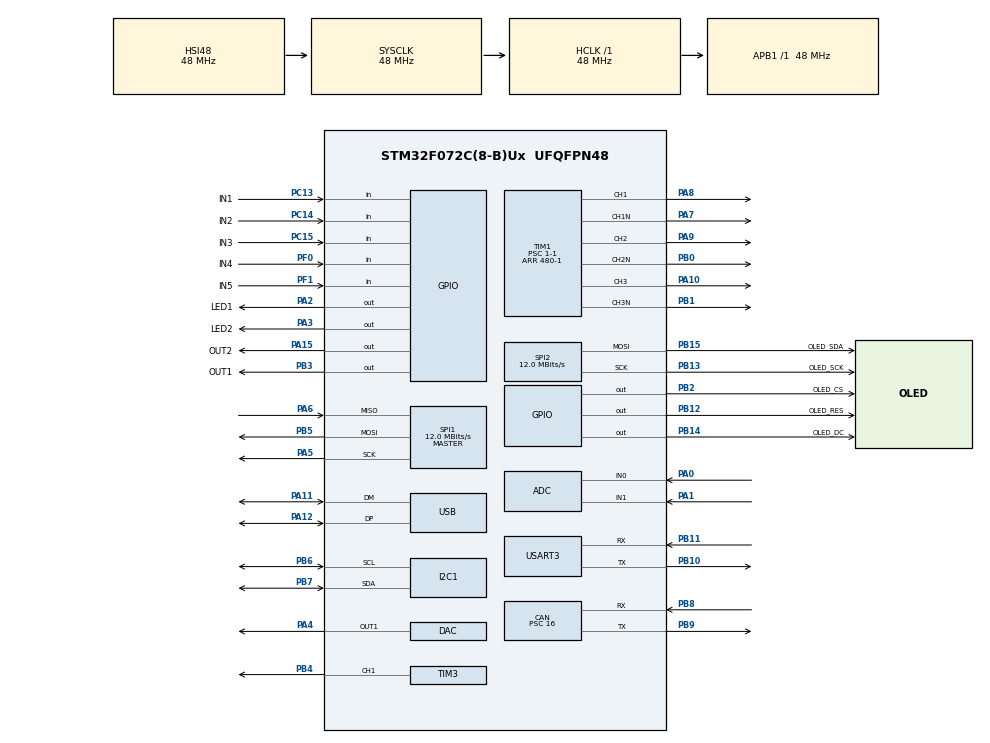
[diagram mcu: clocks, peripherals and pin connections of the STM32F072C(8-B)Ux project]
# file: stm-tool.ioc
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CAN.ABOM=ENABLE
CAN.BS1=CAN_BS1_15TQ
CAN.BS2=CAN_BS2_8TQ
CAN.CalculateBaudRate=125000
CAN.CalculateTimeBit=8000
CAN.CalculateTimeQuantum=333.3333333333333
CAN.NART=ENABLE
CAN.Prescaler=16
CAN.SJW=CAN_SJW_1TQ
CAN.TXFP=DISABLE
Mcu.Family=STM32F0
Mcu.Name=STM32F072C(8-B)Ux
Mcu.Package=UFQFPN48
NVIC.CEC_CAN_IRQn=true\:0\:0\:false\:false\:true\:true\:true\:true
NVIC.TIM15_IRQn=true\:0\:0\:false\:false\:true\:true\:true\:true
NVIC.USB_IRQn=true\:0\:0\:false\:false\:true\:false\:true\:true
PA0.Mode=IN0
PA0.Signal=ADC_IN0
PA1.Mode=IN1
PA1.Signal=ADC_IN1
PA10.Signal=S_TIM1_CH3
PA11.Mode=Device
PA11.Signal=USB_DM
PA12.Mode=Device
PA12.Signal=USB_DP
PA13.Mode=Serial_Wire
PA13.Signal=SYS_SWDIO
PA14.Mode=Serial_Wire
PA14.Signal=SYS_SWCLK
PA15.GPIO_Label=OUT2
PA15.Signal=GPIO_Output
PA2.GPIO_Label=LED1
PA2.Signal=GPIO_Output
PA3.GPIO_Label=LED2
PA3.Signal=GPIO_Output
PA4.Signal=COMP_DAC1_group
PA5.Mode=Full_Duplex_Master
PA5.Signal=SPI1_SCK
PA6.Mode=Full_Duplex_Master
PA6.Signal=SPI1_MISO
PA7.Mode=PWM Generation1 CH1 CH1N
PA7.Signal=TIM1_CH1N
PA8.Signal=S_TIM1_CH1
PA9.Signal=S_TIM1_CH2
PB0.Mode=Output Compare2 CH2 CH2N
PB0.Signal=TIM1_CH2N
PB1.Mode=PWM Generation3 CH3 CH3N
PB1.Signal=TIM1_CH3N
PB10.Mode=Asynchronous
PB10.Signal=USART3_TX
PB11.Mode=Asynchronous
PB11.Signal=USART3_RX
PB12.GPIO_Label=OLED_RES
PB12.GPIO_Speed=GPIO_SPEED_FREQ_HIGH
PB12.Signal=GPIO_Output
PB13.GPIO_Label=OLED_SCK
PB13.Mode=TX_Only_Simplex_Unidirect_Master
PB13.Signal=SPI2_SCK
PB14.GPIO_Label=OLED_DC
PB14.GPIO_Speed=GPIO_SPEED_FREQ_HIGH
PB14.Signal=GPIO_Output
PB15.GPIO_Label=OLED_SDA
PB15.Mode=TX_Only_Simplex_Unidirect_Master
PB15.Signal=SPI2_MOSI
PB2.GPIO_Label=OLED_CS
PB2.GPIO_Speed=GPIO_SPEED_FREQ_HIGH
PB2.Signal=GPIO_Output
PB3.GPIO_Label=OUT1
PB3.Signal=GPIO_Output
PB4.Signal=S_TIM3_CH1
PB5.Mode=Full_Duplex_Master
PB5.Signal=SPI1_MOSI
PB6.Mode=I2C
PB6.Signal=I2C1_SCL
PB7.Mode=I2C
PB7.Signal=I2C1_SDA
PB8.Mode=CAN_Activate
PB8.Signal=CAN_RX
PB9.Mode=CAN_Activate
PB9.Signal=CAN_TX
PC13.GPIO_Label=IN1
PC13.GPIO_PuPd=GPIO_PULLUP
PC13.Signal=GPIO_Input
PC14-OSC32_IN.GPIO_Label=IN2
PC14-OSC32_IN.GPIO_PuPd=GPIO_PULLUP
PC14-OSC32_IN.Signal=GPIO_Input
PC15-OSC32_OUT.GPIO_Label=IN3
PC15-OSC32_OUT.GPIO_PuPd=GPIO_PULLUP
PC15-OSC32_OUT.Signal=GPIO_Input
PF0-OSC_IN.GPIO_Label=IN4
PF0-OSC_IN.GPIO_PuPd=GPIO_PULLUP
PF0-OSC_IN.Signal=GPIO_Input
PF1-OSC_OUT.GPIO_Label=IN5
PF1-OSC_OUT.GPIO_PuPd=GPIO_PULLUP
PF1-OSC_OUT.Signal=GPIO_Input
ProjectManager.HeapSize=0x400
ProjectManager.StackSize=0x800
ProjectManager.TargetToolchain=Makefile
RCC.AHBFreq_Value=48000000
RCC.APB1Freq_Value=48000000
RCC.APB1TimFreq_Value=48000000
RCC.HCLKFreq_Value=48000000
RCC.SYSCLKFreq_VALUE=48000000
RCC.SYSCLKSource=RCC_SYSCLKSOURCE_HSI48
SH.COMP_DAC1_group.0=DAC_OUT1,DAC_OUT1
SH.S_TIM1_CH1.0=TIM1_CH1,PWM Generation1 CH1 CH1N
SH.S_TIM1_CH2.0=TIM1_CH2,Output Compare2 CH2 CH2N
SH.S_TIM1_CH3.0=TIM1_CH3,PWM Generation3 CH3 CH3N
SH.S_TIM3_CH1.0=TIM3_CH1,PWM Generation1 CH1
SPI1.BaudRatePrescaler=SPI_BAUDRATEPRESCALER_4
SPI1.CalculateBaudRate=12.0 MBits/s
SPI1.DataSize=SPI_DATASIZE_8BIT
SPI1.Direction=SPI_DIRECTION_2LINES
SPI1.Mode=SPI_MODE_MASTER
SPI1.VirtualType=VM_MASTER
SPI2.BaudRatePrescaler=SPI_BAUDRATEPRESCALER_4
SPI2.CalculateBaudRate=12.0 MBits/s
SPI2.DataSize=SPI_DATASIZE_8BIT
SPI2.Direction=SPI_DIRECTION_2LINES
SPI2.Mode=SPI_MODE_MASTER
SPI2.NSSPMode=SPI_NSS_PULSE_DISABLE
SPI2.VirtualType=VM_MASTER
TIM1.AutoReloadPreload=TIM_AUTORELOAD_PRELOAD_ENABLE
TIM1.Channel-Output\ Compare2\ CH2\ CH2N=TIM_CHANNEL_2
TIM1.Channel-PWM\ Generation1\ CH1\ CH1N=TIM_CHANNEL_1
TIM1.Channel-PWM\ Generation3\ CH3\ CH3N=TIM_CHANNEL_3
TIM1.DeadTime=5
TIM1.Period=480-1
TIM1.Prescaler=1-1
TIM1.Pulse-Output\ Compare2\ CH2\ CH2N=240
TIM1.Pulse-PWM\ Generation1\ CH1\ CH1N=240
TIM1.Pulse-PWM\ Generation3\ CH3\ CH3N=240
TIM15.AutoReloadPreload=TIM_AUTORELOAD_PRELOAD_ENABLE
TIM15.Channel-PWM\ Generation1\ No\ Output=TIM_CHANNEL_1
TIM15.Channel-PWM\ Generation2\ No\ Output=TIM_CHANNEL_2
TIM15.Period=100-1
TIM15.Prescaler=48-1
TIM15.Pulse-PWM\ Generation1\ No\ Output=10
TIM15.Pulse-PWM\ Generation2\ No\ Output=20
TIM2.Channel-PWM\ Generation1\ CH1=TIM_CHANNEL_1
TIM3.Channel-PWM\ Generation1\ CH1=TIM_CHANNEL_1
USART3.VirtualMode-Asynchronous=VM_ASYNC
USB_DEVICE.CLASS_NAME_FS=CDC
USB_DEVICE.VirtualMode=Cdc
USB_DEVICE.VirtualModeFS=Cdc_FS
VP_TIM15_VS_ClockSourceINT.Mode=Internal
VP_TIM15_VS_no_output1.Mode=PWM Generation1 No Output
VP_TIM15_VS_no_output2.Mode=PWM Generation2 No Output
VP_TIM1_VS_ClockSourceINT.Mode=Internal
VP_TIM2_VS_ClockSourceINT.Mode=Internal
VP_TIM3_VS_ClockSourceINT.Mode=Internal
VP_USB_DEVICE_VS_USB_DEVICE_CDC_FS.Mode=CDC_FS
board=custom

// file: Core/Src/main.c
/* USER CODE BEGIN Header */
/**
  ******************************************************************************
  * @file           : main.c
  * @brief          : Main program body
  ******************************************************************************
  * @attention
  *
  * Copyright (c) 2024 STMicroelectronics.
  * All rights reserved.
  *
  * This software is licensed under terms that can be found in the LICENSE file
  * in the root directory of this software component.
  * If no LICENSE file comes with this software, it is provided AS-IS.
  *
  ******************************************************************************
  */
/* USER CODE END Header */
#include "main.h"
#include "adc.h"
#include "can.h"
#include "dac.h"
#include "i2c.h"
#include "spi.h"
#include "tim.h"
#include "usart.h"
#include "usb_device.h"
#include "gpio.h"

/* USER CODE BEGIN Includes */
#include "loop.h"
#include "shell_port.h"
/* USER CODE END Includes */

void SystemClock_Config(void);

int main(void)
{

  /* MCU Configuration--------------------------------------------------------*/

  /* Reset of all peripherals, Initializes the Flash interface and the Systick. */
  HAL_Init();

  /* Configure the system clock */
  SystemClock_Config();

  /* Initialize all configured peripherals */
  MX_GPIO_Init();
  MX_ADC_Init();
  MX_CAN_Init();
  MX_DAC_Init();
  MX_I2C1_Init();
  MX_SPI1_Init();
  MX_TIM1_Init();
  MX_TIM2_Init();
  MX_TIM3_Init();
  MX_USB_DEVICE_Init();
  MX_SPI2_Init();
  MX_USART3_UART_Init();
  MX_TIM15_Init();
  /* USER CODE BEGIN 2 */
    MY_Init();
    userShellInit();
    uint8_t test[2] = {0x81, 0x12};
    HAL_TIM_PWM_Start(&htim1, TIM_CHANNEL_1);
    HAL_TIMEx_PWMN_Start(&htim1, TIM_CHANNEL_1);
    HAL_TIM_PWM_Start(&htim1, TIM_CHANNEL_2);
    HAL_TIMEx_PWMN_Start(&htim1, TIM_CHANNEL_2);
    HAL_TIM_PWM_Start(&htim1, TIM_CHANNEL_3);
    HAL_TIMEx_PWMN_Start(&htim1, TIM_CHANNEL_3);
  /* USER CODE END 2 */

  /* Infinite loop */
  while (1)
  {

    /* USER CODE BEGIN 3 */
    //CAN_Send(0x123, test, 2);
    RUN_UI();
    USRshellRUN();

  }
  /* USER CODE END 3 */
}

void SystemClock_Config(void)
{
  RCC_OscInitTypeDef RCC_OscInitStruct = {0};
  RCC_ClkInitTypeDef RCC_ClkInitStruct = {0};
  RCC_PeriphCLKInitTypeDef PeriphClkInit = {0};

  /** Initializes the RCC Oscillators according to the specified parameters
  * in the RCC_OscInitTypeDef structure.
  */
  RCC_OscInitStruct.OscillatorType = RCC_OSCILLATORTYPE_HSI|RCC_OSCILLATORTYPE_HSI14
                              |RCC_OSCILLATORTYPE_HSI48;
  RCC_OscInitStruct.HSIState = RCC_HSI_ON;
  RCC_OscInitStruct.HSI48State = RCC_HSI48_ON;
  RCC_OscInitStruct.HSI14State = RCC_HSI14_ON;
  RCC_OscInitStruct.HSICalibrationValue = RCC_HSICALIBRATION_DEFAULT;
  RCC_OscInitStruct.HSI14CalibrationValue = 16;
  RCC_OscInitStruct.PLL.PLLState = RCC_PLL_NONE;
  if (HAL_RCC_OscConfig(&RCC_OscInitStruct) != HAL_OK)
  {
    Error_Handler();
  }

  /** Initializes the CPU, AHB and APB buses clocks
  */
  RCC_ClkInitStruct.ClockType = RCC_CLOCKTYPE_HCLK|RCC_CLOCKTYPE_SYSCLK
                              |RCC_CLOCKTYPE_PCLK1;
  RCC_ClkInitStruct.SYSCLKSource = RCC_SYSCLKSOURCE_HSI48;
  RCC_ClkInitStruct.AHBCLKDivider = RCC_SYSCLK_DIV1;
  RCC_ClkInitStruct.APB1CLKDivider = RCC_HCLK_DIV1;

  if (HAL_RCC_ClockConfig(&RCC_ClkInitStruct, FLASH_LATENCY_1) != HAL_OK)
  {
    Error_Handler();
  }
  PeriphClkInit.PeriphClockSelection = RCC_PERIPHCLK_USB|RCC_PERIPHCLK_I2C1;
  PeriphClkInit.I2c1ClockSelection = RCC_I2C1CLKSOURCE_HSI;
  PeriphClkInit.UsbClockSelection = RCC_USBCLKSOURCE_HSI48;

  if (HAL_RCCEx_PeriphCLKConfig(&PeriphClkInit) != HAL_OK)
  {
    Error_Handler();
  }
}

void Error_Handler(void)
{
  __disable_irq();
  while (1)
  {
  }
}
